# iND83216 register map
Vendor: Indiemicro; Series: RealplumTiny; File version: 1.00
CPU: CM0 r0p1, selectable endian, no MPU, no FPU, 4 interrupt priority bits
Registers are 32-bit, read-write, no defined reset value unless marked. A register's access mark holds for its fields unless they carry their own. Offsets are from the block's base; [hi:lo] are bit positions; {n}, {i} and the like mark numbered series.

## SYSCTRLA — System configuration and retention memory
Base 0x50000800; register names take the prefix SYSCTRLA_
0x00 RETAIN1 — Retained data 1
  [15:0] RETAIN1 — Firmware scratch register 1 (0x1). Contents retained in Deepsleep mode - but lost after hibernate mode and hard reset.
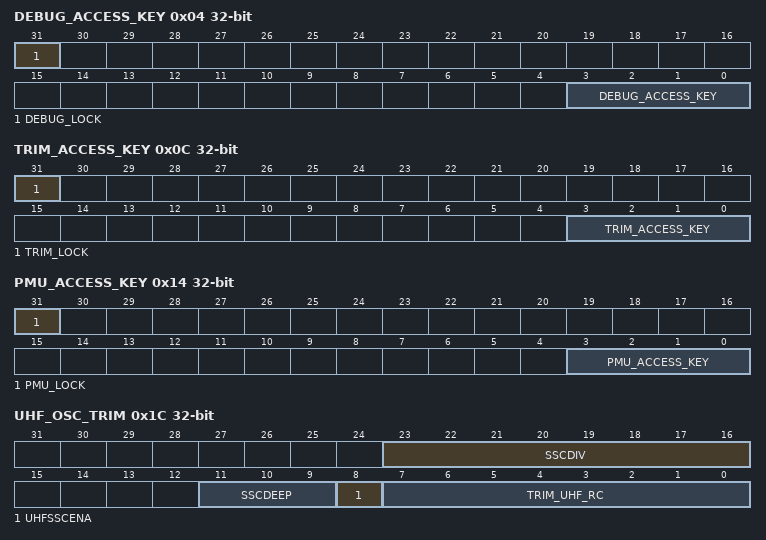
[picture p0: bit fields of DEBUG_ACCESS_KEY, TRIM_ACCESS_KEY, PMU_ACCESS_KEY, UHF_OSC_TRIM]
0x04 DEBUG_ACCESS_KEY
  [31] DEBUG_LOCK — Set Only bit. Set this bit to lock DEBUG_CODE bits.
  [3:0] DEBUG_ACCESS_KEY — Write the value 0x5 to this register to enable debug options. Write any other value to disable the debug options.
0x08 DEBUG_ACCESS_ENABLED
  [0] DEBUG_ACCESS_ENABLED ro — A status flag that is set when debug access is enabled
0x0C TRIM_ACCESS_KEY
  [31] TRIM_LOCK — Set Only bit. Write 1 to this bit to lock TRIM_CODE bits.
  [3:0] TRIM_ACCESS_KEY — Write the value 0xe to this register to enable 'trim access' (which allows write access to various trim settings and production test options). Write any other value to disable trim access.
0x10 TRIM_ACCESS_ENABLED
  [0] TRIM_ACCESS_ENABLED ro — A status flag that is set when trim access is enabled
0x14 PMU_ACCESS_KEY — PMU configure access key
  [31] PMU_LOCK — Set Only bit. Set this bit to lock PMU_CODE bits.
  [3:0] PMU_ACCESS_KEY — Write the value 0xA to this register to enable 1v5 domain at hibernate. Write any other value to disable the 1v5 domain at hibernate.
0x18 PMU_ACCESS_ENABLED — PMU configure access enabled
  [0] PMU_ACCESS_ENABLED ro — A status flag that is set when pmu access is enabled
0x1C UHF_OSC_TRIM — Trim controls for the ultra high frequency (48MHz) oscillator
  [23:16] SSCDIV — SSC Clock Divider. SSC Freq = SYS_FREQ/[(SSC_DIV+1)*(SSC_DEEP+1)*4].
  [11:9] SSCDEEP — SSC Depth Configuration.
  [8] UHFSSCENA — UHF Oscillator SSC Enable. SSC_DEEP and SSC_DIV fields are shared with HF_OSC_TRIM register.
  [7:0] TRIM_UHF_RC — Ultra High Frequency RC Oscillator trim. TRIM bits will be changed if SSC is enabled. Reload the trim bits from Flash should be executed by software if SSC is disabled from enable state. Following value only used as a reference:0x0: freq=20MHz0x96: freq=48MHz0xff: freq=100MHz NOTE1: The trimmed frequency is non-linear with trim value NOTE2: Can only modified when TRIM_ACCESS_ENABLED is enabled.
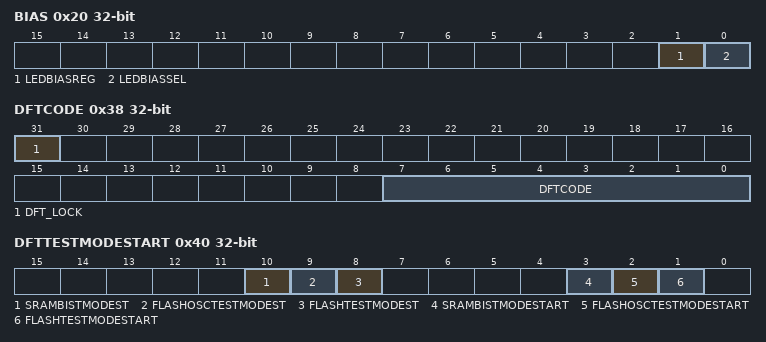
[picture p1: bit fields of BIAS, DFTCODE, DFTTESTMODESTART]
0x20 BIAS — Bias Control
  [1] LEDBIASREG — High Voltage LED bias select register. If LED_BIAS_SEL is set, then LED_BIAS_REG allows override access to the LED BIAS signal.
  [0] LEDBIASSEL — High Voltage LED bias select. 0x0: The LED Bias is enabled and disabled by the pmu hardware state machine by default.0x1: The value of the LED_BIAS_REG field is what is used to drive the LED_BIAS signal. (override mode)
0x24 TRIMLEDBIAS — LED bias current Trim
  [7:0] LEDBIASTRIM — LED bias current trim. each code is about 50nA step.wirte trim key
{0x28+4i} TRIMLED{i} (i=0..2) — High Voltage LED trim
  [24:16] TRIM{i} — LED trim (120uA step; max about 60mA).
0x34 TRIMVFW — LED Current Trim
  [7:0] TRIMVFW — LED Current trim (10uA step max about 2.56mA).
0x38 DFTCODE — DFT Unlock Code
  [31] DFT_LOCK — Set Only bit. Write 1 to this bit to lock FLASH_TEST_MODE and FLASH_OSC_TEST_MODE.
  [7:0] DFTCODE wo — Test Mode Unlock Enable Code. 0x1C needs to be written to this register to unlock the FLASH_TEST_MODE_START and FLASH_OSC_TEST_MODE_START registers.
0x3C DFT_ACCESS_ENABLED
  [0] DFT_ACCESS_ENABLED ro — A status flag that is set when FLASH_TEST_MODE_START and FLASH_OSC_TEST_MODE_START registers access are enabled.
0x40 DFTTESTMODESTART — DFT Mode Start
  [10] SRAMBISTMODEST — Indicate chip is in sram bist mode. Write 1 can quit test mode
  [9] FLASHOSCTESTMODEST — Indicate chip is in flash oscillator test mode. Write 1 can quit test mode
  [8] FLASHTESTMODEST — Indicate chip is in flash test mode. Write 1 can quit test mode
  [3] SRAMBISTMODESTART wo — Puts chip into sram bist mode.
  [2] FLASHOSCTESTMODESTART wo — Puts chip into flash oscillator test mode.
  [1] FLASHTESTMODESTART wo — Puts chip into flash test mode.
0x44 NAME — ASIC name
  [31:0] NAME ro — ASIC name. A read from this register will return the Chip name
0x48 REV — Silicon Revision
  [15:0] REV ro — Silicon Revision. A read from this register will return the ASCII silicon revision (e.g. ASCII A0 is 0x4130)
